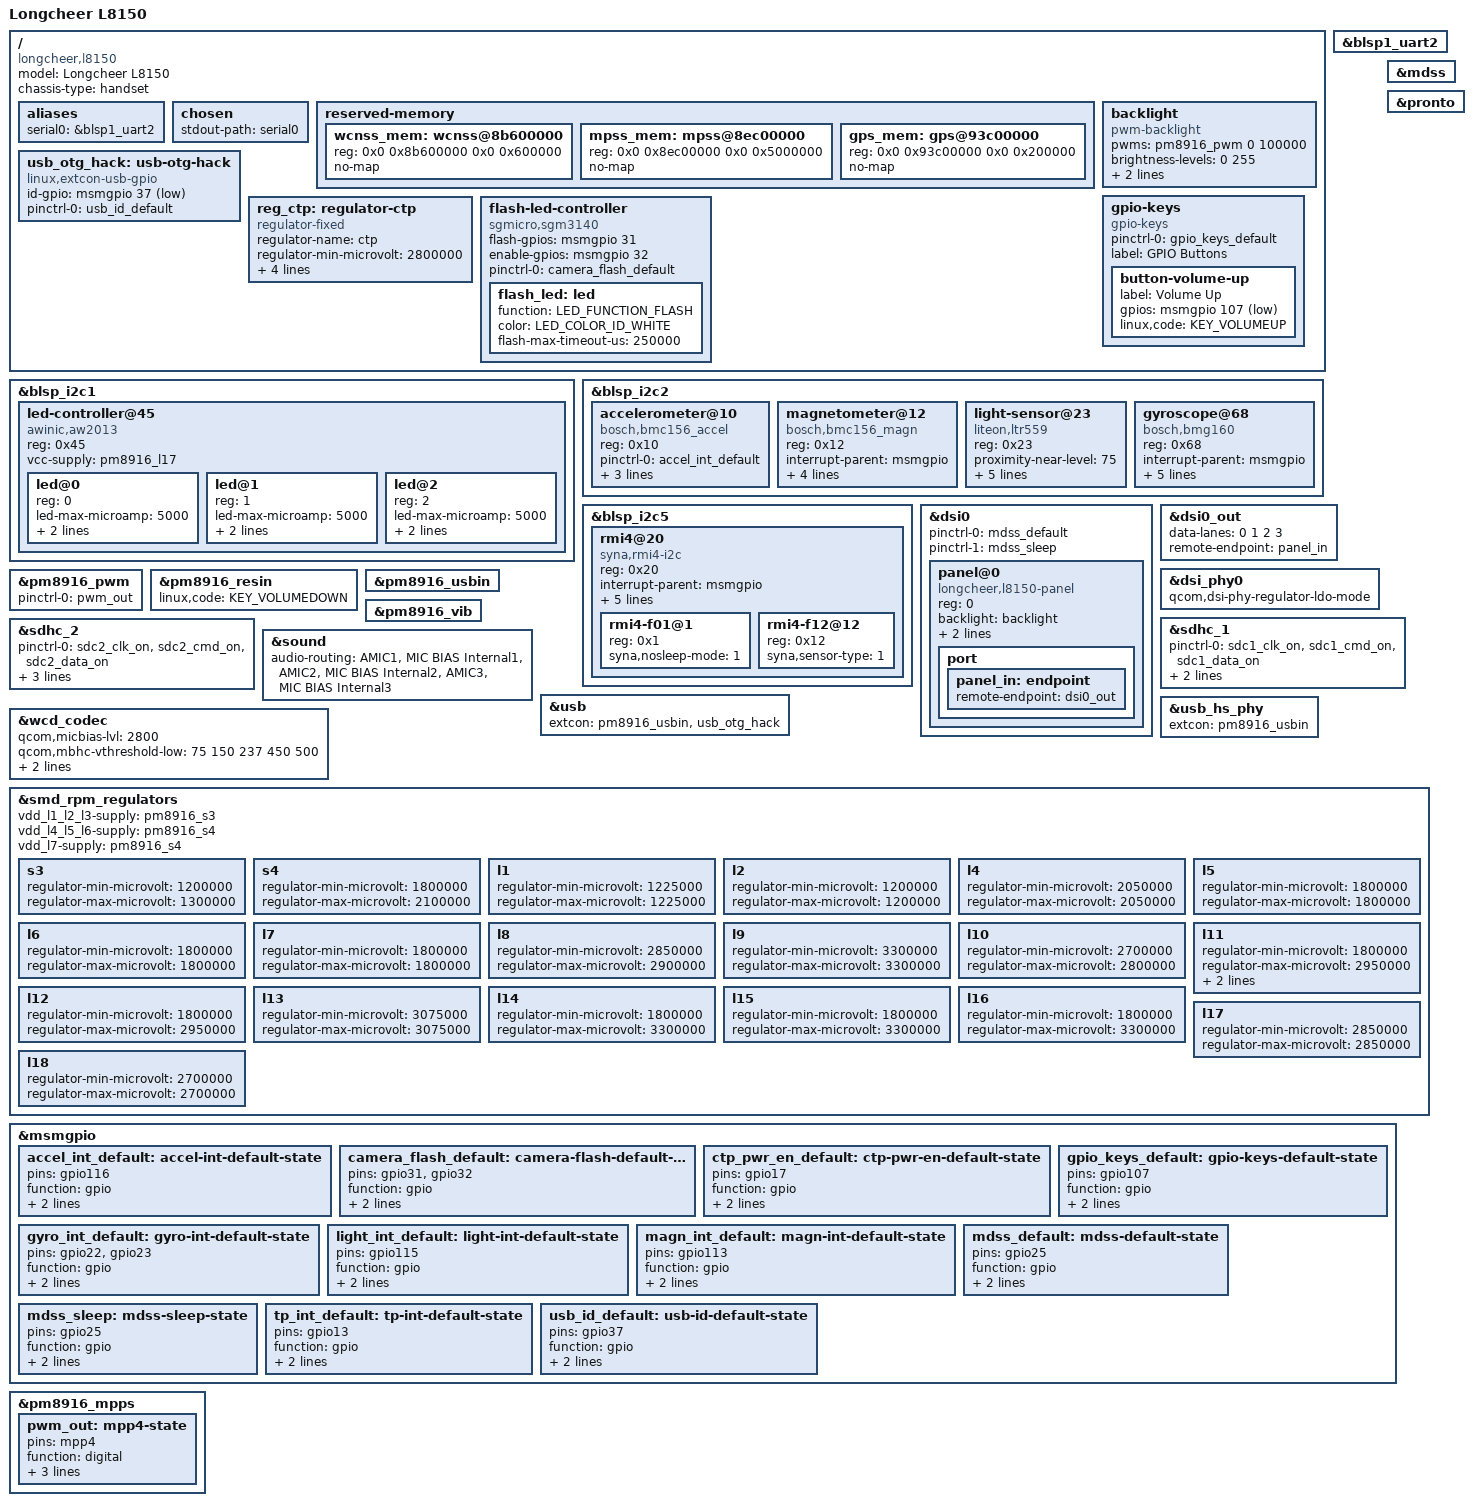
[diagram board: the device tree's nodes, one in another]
// SPDX-License-Identifier: GPL-2.0-only

/dts-v1/;

#include "msm8916-pm8916.dtsi"
#include "msm8916-modem.dtsi"

#include <dt-bindings/gpio/gpio.h>
#include <dt-bindings/input/input.h>
#include <dt-bindings/interrupt-controller/irq.h>
#include <dt-bindings/leds/common.h>
#include <dt-bindings/pinctrl/qcom,pmic-mpp.h>

/delete-node/ &mpss_mem;
/delete-node/ &wcnss_mem;

/ {
	model = "Longcheer L8150";
	compatible = "longcheer,l8150", "qcom,msm8916-v1-qrd/9-v1", "qcom,msm8916";
	chassis-type = "handset";

	aliases {
		serial0 = &blsp1_uart2;
	};

	chosen {
		stdout-path = "serial0";
	};

	/*
	 * For some reason, the wcnss firmware is not relocatable, it must be
	 * loaded at 0x8b600000. Unfortunately this overlaps with the memory
	 * region required for the modem (0x86800000-0x8b800000).
	 *
	 * On the downstream kernel everything somehow works even with the
	 * overlap (possibly because wcnss is loaded after the modem
	 * and the modem never accessed its last 2 MB memory...?)
	 *
	 * Fortunately at least the modem is relocatable (aligned to 0x400000),
	 * so put it after everything else and keep the original region empty.
	 */
	reserved-memory {
		wcnss_mem: wcnss@8b600000 {
			reg = <0x0 0x8b600000 0x0 0x600000>;
			no-map;
		};

		mpss_mem: mpss@8ec00000 {
			reg = <0x0 0x8ec00000 0x0 0x5000000>;
			no-map;
		};

		gps_mem: gps@93c00000 {
			reg = <0x0 0x93c00000 0x0 0x200000>;
			no-map;
		};
	};

	backlight: backlight {
		compatible = "pwm-backlight";
		pwms = <&pm8916_pwm 0 100000>;

		brightness-levels = <0 255>;
		num-interpolated-steps = <255>;
		default-brightness-level = <255>;
	};

	usb_otg_hack: usb-otg-hack {
		compatible = "linux,extcon-usb-gpio";

		/*
		 * NOTE: This allows detection of custom-made OTG adapters
		 *
		 * Since L8150 doesn't support OTG it's impossible to use normal OTG
		 * adapters. However since USB_ID is in fact connected to GPIO it's
		 * possible to detect custom-made OTG adapters that connect USB_ID
		 * to 5v instead of GND and provie external power.
		 *
		 * Downside of this approach is that USB_ID pin is used to change boot
		 * order of SoC and if device will be powered on with adapter attached
		 * and powered, it will boot into USB BOOT mode.
		 */
		id-gpio = <&msmgpio 37 GPIO_ACTIVE_LOW>;
		pinctrl-0 = <&usb_id_default>;
		pinctrl-names = "default";
	};

	gpio-keys {
		compatible = "gpio-keys";

		pinctrl-0 = <&gpio_keys_default>;
		pinctrl-names = "default";

		label = "GPIO Buttons";

		button-volume-up {
			label = "Volume Up";
			gpios = <&msmgpio 107 GPIO_ACTIVE_LOW>;
			linux,code = <KEY_VOLUMEUP>;
		};
	};

	reg_ctp: regulator-ctp {
		compatible = "regulator-fixed";
		regulator-name = "ctp";

		regulator-min-microvolt = <2800000>;
		regulator-max-microvolt = <2800000>;

		gpio = <&msmgpio 17 GPIO_ACTIVE_HIGH>;
		enable-active-high;

		pinctrl-0 = <&ctp_pwr_en_default>;
		pinctrl-names = "default";
	};

	flash-led-controller {
		compatible = "sgmicro,sgm3140";
		flash-gpios = <&msmgpio 31 GPIO_ACTIVE_HIGH>;
		enable-gpios = <&msmgpio 32 GPIO_ACTIVE_HIGH>;

		pinctrl-0 = <&camera_flash_default>;
		pinctrl-names = "default";

		flash_led: led {
			function = LED_FUNCTION_FLASH;
			color = <LED_COLOR_ID_WHITE>;
			flash-max-timeout-us = <250000>;
		};
	};
};

&blsp_i2c1 {
	status = "okay";

	led-controller@45 {
		compatible = "awinic,aw2013";
		reg = <0x45>;
		#address-cells = <1>;
		#size-cells = <0>;

		vcc-supply = <&pm8916_l17>;

		led@0 {
			reg = <0>;
			led-max-microamp = <5000>;
			function = LED_FUNCTION_INDICATOR;
			color = <LED_COLOR_ID_RED>;
		};

		led@1 {
			reg = <1>;
			led-max-microamp = <5000>;
			function = LED_FUNCTION_INDICATOR;
			color = <LED_COLOR_ID_GREEN>;
		};

		led@2 {
			reg = <2>;
			led-max-microamp = <5000>;
			function = LED_FUNCTION_INDICATOR;
			color = <LED_COLOR_ID_BLUE>;
		};
	};
};

&blsp_i2c2 {
	status = "okay";

	accelerometer@10 {
		compatible = "bosch,bmc156_accel";
		reg = <0x10>;

		/*
		 * For some reason the interrupt line is usually not connected
		 * to the BMC156. However, there are two pads next to the chip
		 * that can be shorted to make it work if needed.
		 *
		 * interrupt-parent = <&msmgpio>;
		 * interrupts = <116 IRQ_TYPE_EDGE_RISING>;
		 */

		pinctrl-0 = <&accel_int_default>;
		pinctrl-names = "default";

		vdd-supply = <&pm8916_l17>;
		vddio-supply = <&pm8916_l6>;

		mount-matrix = "0", "1", "0",
			      "-1", "0", "0",
			       "0", "0", "1";
	};

	magnetometer@12 {
		compatible = "bosch,bmc156_magn";
		reg = <0x12>;

		interrupt-parent = <&msmgpio>;
		interrupts = <113 IRQ_TYPE_EDGE_RISING>;

		pinctrl-0 = <&magn_int_default>;
		pinctrl-names = "default";

		vdd-supply = <&pm8916_l17>;
		vddio-supply = <&pm8916_l6>;
	};

	light-sensor@23 {
		compatible = "liteon,ltr559";
		reg = <0x23>;
		proximity-near-level = <75>;

		interrupt-parent = <&msmgpio>;
		interrupts = <115 IRQ_TYPE_EDGE_FALLING>;

		pinctrl-0 = <&light_int_default>;
		pinctrl-names = "default";

		vdd-supply = <&pm8916_l17>;
		vio-supply = <&pm8916_l6>;
	};

	gyroscope@68 {
		compatible = "bosch,bmg160";
		reg = <0x68>;

		interrupt-parent = <&msmgpio>;
		interrupts = <23 IRQ_TYPE_EDGE_RISING>,
			     <22 IRQ_TYPE_EDGE_RISING>;

		pinctrl-0 = <&gyro_int_default>;
		pinctrl-names = "default";

		vdd-supply = <&pm8916_l17>;
		vddio-supply = <&pm8916_l6>;
	};
};

&blsp_i2c5 {
	status = "okay";

	rmi4@20 {
		compatible = "syna,rmi4-i2c";
		reg = <0x20>;
		#address-cells = <1>;
		#size-cells = <0>;

		interrupt-parent = <&msmgpio>;
		interrupts = <13 IRQ_TYPE_EDGE_FALLING>;

		vdd-supply = <&reg_ctp>;
		vio-supply = <&pm8916_l6>;

		pinctrl-0 = <&tp_int_default>;
		pinctrl-names = "default";

		syna,startup-delay-ms = <10>;

		rmi4-f01@1 {
			reg = <0x1>;
			syna,nosleep-mode = <1>; /* Allow sleeping */
		};

		rmi4-f12@12 {
			reg = <0x12>;
			syna,sensor-type = <1>; /* Touchscreen */
		};
	};
};

&blsp1_uart2 {
	status = "okay";
};

&dsi0 {
	pinctrl-0 = <&mdss_default>;
	pinctrl-1 = <&mdss_sleep>;
	pinctrl-names = "default", "sleep";

	panel@0 {
		compatible = "longcheer,l8150-panel";
		reg = <0>;

		backlight = <&backlight>;
		power-supply = <&pm8916_l17>;
		reset-gpios = <&msmgpio 25 GPIO_ACTIVE_LOW>;

		port {
			panel_in: endpoint {
				remote-endpoint = <&dsi0_out>;
			};
		};
	};
};

&dsi0_out {
	data-lanes = <0 1 2 3>;
	remote-endpoint = <&panel_in>;
};

&dsi_phy0 {
	qcom,dsi-phy-regulator-ldo-mode;
};

&mdss {
	status = "okay";
};

&pm8916_pwm {
	pinctrl-0 = <&pwm_out>;
	pinctrl-names = "default";
	status = "okay";
};

&pm8916_resin {
	linux,code = <KEY_VOLUMEDOWN>;
	status = "okay";
};

&pm8916_usbin {
	status = "okay";
};

&pm8916_vib {
	status = "okay";
};

&pronto {
	status = "okay";
};

&sdhc_1 {
	pinctrl-0 = <&sdc1_clk_on &sdc1_cmd_on &sdc1_data_on>;
	pinctrl-1 = <&sdc1_clk_off &sdc1_cmd_off &sdc1_data_off>;
	pinctrl-names = "default", "sleep";

	status = "okay";
};

&sdhc_2 {
	pinctrl-0 = <&sdc2_clk_on &sdc2_cmd_on &sdc2_data_on>;
	pinctrl-1 = <&sdc2_clk_off &sdc2_cmd_off &sdc2_data_off>;
	pinctrl-names = "default", "sleep";

	non-removable;

	status = "okay";
};

&sound {
	audio-routing =
		"AMIC1", "MIC BIAS Internal1",
		"AMIC2", "MIC BIAS Internal2",
		"AMIC3", "MIC BIAS Internal3";
	status = "okay";
};

&usb {
	extcon = <&pm8916_usbin>, <&usb_otg_hack>;
	status = "okay";
};

&usb_hs_phy {
	extcon = <&pm8916_usbin>;
};

&wcd_codec {
	qcom,micbias-lvl = <2800>;
	qcom,mbhc-vthreshold-low = <75 150 237 450 500>;
	qcom,mbhc-vthreshold-high = <75 150 237 450 500>;
	qcom,hphl-jack-type-normally-open;
};

&smd_rpm_regulators {
	vdd_l1_l2_l3-supply = <&pm8916_s3>;
	vdd_l4_l5_l6-supply = <&pm8916_s4>;
	vdd_l7-supply = <&pm8916_s4>;

	s3 {
		regulator-min-microvolt = <1200000>;
		regulator-max-microvolt = <1300000>;
	};

	s4 {
		regulator-min-microvolt = <1800000>;
		regulator-max-microvolt = <2100000>;
	};

	l1 {
		regulator-min-microvolt = <1225000>;
		regulator-max-microvolt = <1225000>;
	};

	l2 {
		regulator-min-microvolt = <1200000>;
		regulator-max-microvolt = <1200000>;
	};

	l4 {
		regulator-min-microvolt = <2050000>;
		regulator-max-microvolt = <2050000>;
	};

	l5 {
		regulator-min-microvolt = <1800000>;
		regulator-max-microvolt = <1800000>;
	};

	l6 {
		regulator-min-microvolt = <1800000>;
		regulator-max-microvolt = <1800000>;
	};

	l7 {
		regulator-min-microvolt = <1800000>;
		regulator-max-microvolt = <1800000>;
	};

	l8 {
		regulator-min-microvolt = <2850000>;
		regulator-max-microvolt = <2900000>;
	};

	l9 {
		regulator-min-microvolt = <3300000>;
		regulator-max-microvolt = <3300000>;
	};

	l10 {
		regulator-min-microvolt = <2700000>;
		regulator-max-microvolt = <2800000>;
	};

	l11 {
		regulator-min-microvolt = <1800000>;
		regulator-max-microvolt = <2950000>;
		regulator-system-load = <200000>;
		regulator-allow-set-load;
	};

	l12 {
		regulator-min-microvolt = <1800000>;
		regulator-max-microvolt = <2950000>;
	};

	l13 {
		regulator-min-microvolt = <3075000>;
		regulator-max-microvolt = <3075000>;
	};

	l14 {
		regulator-min-microvolt = <1800000>;
		regulator-max-microvolt = <3300000>;
	};

	l15 {
		regulator-min-microvolt = <1800000>;
		regulator-max-microvolt = <3300000>;
	};

	l16 {
		regulator-min-microvolt = <1800000>;
		regulator-max-microvolt = <3300000>;
	};

	l17 {
		regulator-min-microvolt = <2850000>;
		regulator-max-microvolt = <2850000>;
	};

	l18 {
		regulator-min-microvolt = <2700000>;
		regulator-max-microvolt = <2700000>;
	};
};

&msmgpio {
	accel_int_default: accel-int-default-state {
		pins = "gpio116";
		function = "gpio";
		drive-strength = <2>;
		bias-disable;
	};

	camera_flash_default: camera-flash-default-state {
		pins = "gpio31", "gpio32";
		function = "gpio";
		drive-strength = <2>;
		bias-disable;
	};

	ctp_pwr_en_default: ctp-pwr-en-default-state {
		pins = "gpio17";
		function = "gpio";
		drive-strength = <2>;
		bias-disable;
	};

	gpio_keys_default: gpio-keys-default-state {
		pins = "gpio107";
		function = "gpio";
		drive-strength = <2>;
		bias-pull-up;
	};

	gyro_int_default: gyro-int-default-state {
		pins = "gpio22", "gpio23";
		function = "gpio";
		drive-strength = <2>;
		bias-disable;
	};

	light_int_default: light-int-default-state {
		pins = "gpio115";
		function = "gpio";
		drive-strength = <2>;
		bias-disable;
	};

	magn_int_default: magn-int-default-state {
		pins = "gpio113";
		function = "gpio";
		drive-strength = <2>;
		bias-disable;
	};

	mdss_default: mdss-default-state {
		pins = "gpio25";
		function = "gpio";
		drive-strength = <8>;
		bias-disable;
	};

	mdss_sleep: mdss-sleep-state {
		pins = "gpio25";
		function = "gpio";
		drive-strength = <2>;
		bias-pull-down;
	};

	tp_int_default: tp-int-default-state {
		pins = "gpio13";
		function = "gpio";
		drive-strength = <2>;
		bias-disable;
	};

	usb_id_default: usb-id-default-state {
		pins = "gpio37";
		function = "gpio";
		drive-strength = <2>;
		bias-pull-down;
	};
};

&pm8916_mpps {
	pwm_out: mpp4-state {
		pins = "mpp4";
		function = "digital";
		power-source = <PM8916_MPP_VPH>;
		output-low;
		qcom,dtest = <1>;
	};
};
